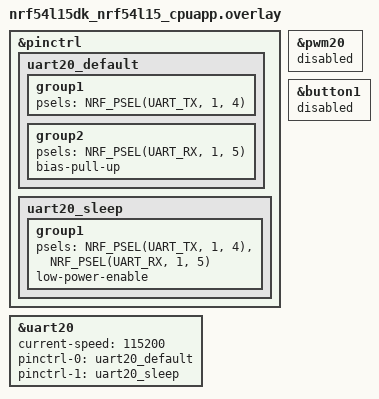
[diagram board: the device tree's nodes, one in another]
/*
 * MCUBoot console: 与 demo / eink_tag rev_b 自有板一致。
 * TX=P1.04 RX=P1.05，避免 Boot 与 APP 串口脚不一致看不到日志。
 */

#include <zephyr/dt-bindings/pinctrl/nrf-pinctrl.h>

&pinctrl {
	uart20_default: uart20_default {
		group1 {
			psels = <NRF_PSEL(UART_TX, 1, 4)>;
		};
		group2 {
			psels = <NRF_PSEL(UART_RX, 1, 5)>;
			bias-pull-up;
		};
	};

	uart20_sleep: uart20_sleep {
		group1 {
			psels = <NRF_PSEL(UART_TX, 1, 4)>,
				<NRF_PSEL(UART_RX, 1, 5)>;
			low-power-enable;
		};
	};
};

&uart20 {
	status = "okay";
	current-speed = <115200>;
	pinctrl-0 = <&uart20_default>;
	pinctrl-1 = <&uart20_sleep>;
	pinctrl-names = "default", "sleep";
};

/* Avoid DK conflicts with our UART pins */
&pwm20 {
	status = "disabled";
};

&button1 {
	status = "disabled";
};
